VERSION "DBC_EATON_MVEC"

NS_ :

BS_:

BU_:

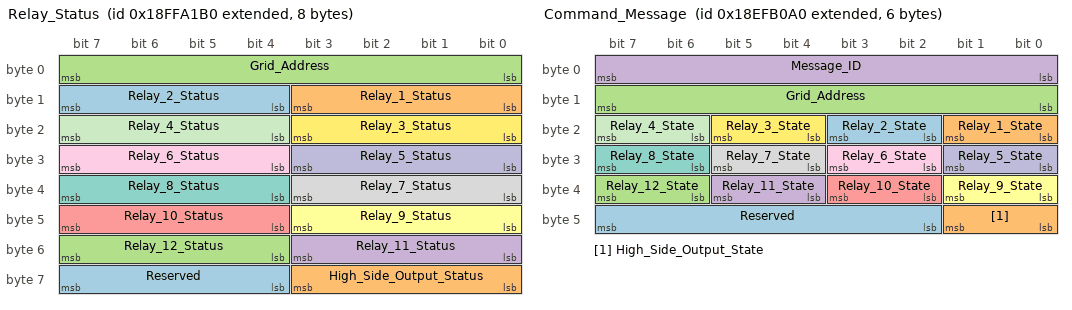
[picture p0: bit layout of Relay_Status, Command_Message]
BO_ 2566889904 Relay_Status: 8 Vector__XXX
 SG_ Reserved : 60|4@1+ (1,0) [0|15] "" Vector__XXX
 SG_ High_Side_Output_Status : 56|4@1+ (1,0) [0|15] "" Vector__XXX
 SG_ Relay_12_Status : 52|4@1+ (1,0) [0|15] "" Vector__XXX
 SG_ Relay_11_Status : 48|4@1+ (1,0) [0|15] "" Vector__XXX
 SG_ Relay_10_Status : 44|4@1+ (1,0) [0|15] "" Vector__XXX
 SG_ Relay_9_Status : 40|4@1+ (1,0) [0|15] "" Vector__XXX
 SG_ Relay_8_Status : 36|4@1+ (1,0) [0|15] "" Vector__XXX
 SG_ Relay_7_Status : 32|4@1+ (1,0) [0|15] "" Vector__XXX
 SG_ Relay_6_Status : 28|4@1+ (1,0) [0|15] "" Vector__XXX
 SG_ Relay_5_Status : 24|4@1+ (1,0) [0|15] "" Vector__XXX
 SG_ Relay_4_Status : 20|4@1+ (1,0) [0|15] "" Vector__XXX
 SG_ Relay_3_Status : 16|4@1+ (1,0) [0|15] "" Vector__XXX
 SG_ Relay_2_Status : 12|4@1+ (1,0) [0|15] "" Vector__XXX
 SG_ Relay_1_Status : 8|4@1+ (1,0) [0|15] "" Vector__XXX
 SG_ Grid_Address : 0|8@1+ (1,0) [0|255] "" Vector__XXX

BO_ 2565845152 Command_Message: 6 Vector__XXX
 SG_ Reserved : 42|6@1+ (1,0) [0|63] "" Vector__XXX
 SG_ High_Side_Output_State : 40|2@1+ (1,0) [0|3] "" Vector__XXX
 SG_ Relay_12_State : 38|2@1+ (1,0) [0|3] "" Vector__XXX
 SG_ Relay_11_State : 36|2@1+ (1,0) [0|3] "" Vector__XXX
 SG_ Relay_10_State : 34|2@1+ (1,0) [0|3] "" Vector__XXX
 SG_ Relay_9_State : 32|2@1+ (1,0) [0|3] "" Vector__XXX
 SG_ Relay_8_State : 30|2@1+ (1,0) [0|3] "" Vector__XXX
 SG_ Relay_7_State : 28|2@1+ (1,0) [0|3] "" Vector__XXX
 SG_ Relay_6_State : 26|2@1+ (1,0) [0|3] "" Vector__XXX
 SG_ Relay_5_State : 24|2@1+ (1,0) [0|3] "" Vector__XXX
 SG_ Relay_4_State : 22|2@1+ (1,0) [0|3] "" Vector__XXX
 SG_ Relay_3_State : 20|2@1+ (1,0) [0|3] "" Vector__XXX
 SG_ Relay_2_State : 18|2@1+ (1,0) [0|3] "" Vector__XXX
 SG_ Relay_1_State : 16|2@1+ (1,0) [0|3] "" Vector__XXX
 SG_ Grid_Address : 8|8@1+ (1,0) [0|255] "" Vector__XXX
 SG_ Message_ID : 0|8@1+ (1,0) [0|255] "" Vector__XXX

CM_ SG_ 2565845152 Message_ID "0x88 - Command";
BA_DEF_  "BusType" STRING ;
BA_DEF_DEF_  "BusType" "CAN";
